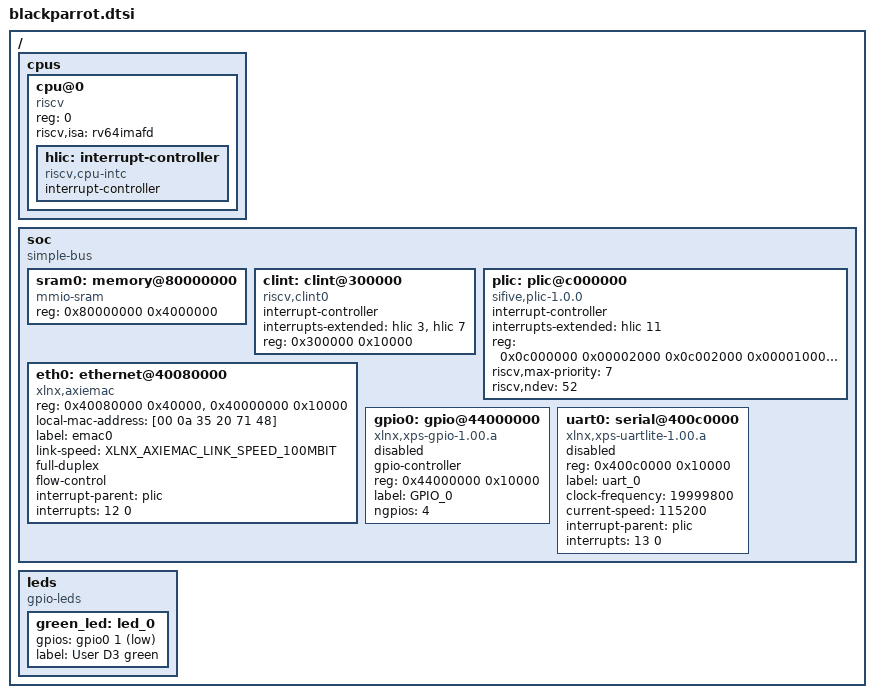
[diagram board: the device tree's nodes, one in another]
/*
 * Copyright (c) 2018 Linaro Limited
 *
 * SPDX-License-Identifier: Apache-2.0
 */
#include <dt-bindings/ethernet/xlnx_axiemac.h>
/ {
	#address-cells = <1>;
	#size-cells = <1>;

	cpus {
		#address-cells = <1>;
		#size-cells = <0>;
		cpu@0 {
			compatible = "riscv";
			device_type = "cpu";
			reg = <0>;
			riscv,isa = "rv64imafd";
			
			hlic: interrupt-controller {
				#interrupt-cells = <1>;
				compatible = "riscv,cpu-intc";
				interrupt-controller;
			};
		};
	};

	soc {
		#address-cells = <1>;
		#size-cells = <1>;
		compatible = "simple-bus";
		ranges;

		sram0: memory@80000000 {
			compatible = "mmio-sram";
			reg = <0x80000000 0x4000000>;
		};

		clint: clint@300000 {
			#interrupt-cells = <1>;
			compatible = "riscv,clint0";
			interrupt-controller;
			interrupts-extended = <&hlic 3 &hlic 7>;
			reg = <0x300000 0x10000>;
			reg-names = "control";
		};
    
		plic: plic@c000000 {
			#interrupt-cells = <2>;
			compatible = "sifive,plic-1.0.0";
			interrupt-controller;
			interrupts-extended = <&hlic 11>;
			reg = <0x0c000000 0x00002000
			       0x0c002000 0x00001000
			       0x0c008000 0x00000010>;                    
			reg-names = "prio", "irq_en", "reg";
			riscv,max-priority = <7>;
			riscv,ndev = <52>;
		};
    
    eth0: ethernet@40080000 {
			compatible = "xlnx,axiemac";
			reg = <0x40080000 0x40000>,
				<0x40000000 0x10000>;
      local-mac-address = [00 0a 35 20 71 48];
      status = "ok";
      label = "emac0";
			link-speed = <XLNX_AXIEMAC_LINK_SPEED_100MBIT>;
      full-duplex;
      flow-control;
      interrupt-parent = <&plic>;
      interrupts = <12 0>;
		};
    
    gpio0: gpio@44000000 {
			compatible = "xlnx,xps-gpio-1.00.a";
      gpio-controller;
			reg = <0x44000000 0x10000>;
			label = "GPIO_0";
			#gpio-cells = <2>;
      ngpios = <4>;
      status = "disabled";
		};
    
    uart0: serial@400c0000 {
			compatible = "xlnx,xps-uartlite-1.00.a";
			reg = <0x400c0000 0x10000>;
			label = "uart_0";
			clock-frequency = <19999800>;
			current-speed = <115200>;
			status = "enable";
      interrupt-parent = <&plic>;
      interrupts = <13 0>;
		};
	};
  
	leds {
		compatible = "gpio-leds";
		green_led: led_0 {
			gpios = <&gpio0 1 GPIO_ACTIVE_LOW>;
			label = "User D3 green";
		};
	};

};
